VERSION ""

NS_ :

BS_:

BU_: ZOMBIE LEAFSIM

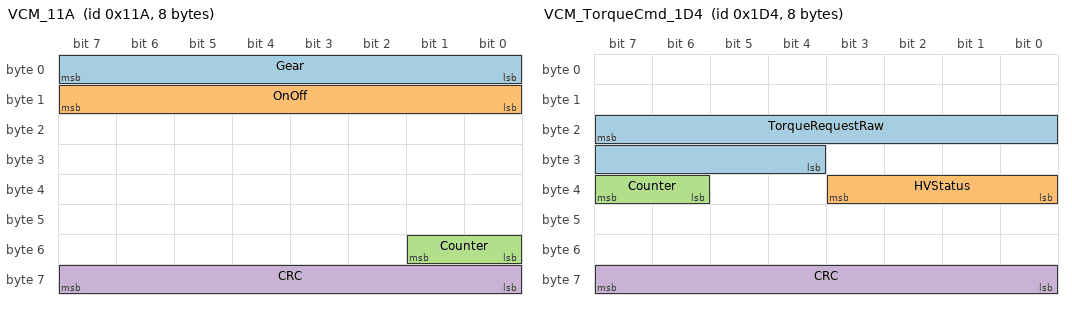
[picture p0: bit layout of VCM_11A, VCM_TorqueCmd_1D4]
BO_ 282 VCM_11A: 8 ZOMBIE
 SG_ Gear : 0|8@1+ (1,0) [0|255] "" LEAFSIM
 SG_ OnOff : 8|8@1+ (1,0) [0|255] "" LEAFSIM
 SG_ Counter : 48|2@1+ (1,0) [0|3] "" LEAFSIM
 SG_ CRC : 56|8@1+ (1,0) [0|255] "" LEAFSIM

BO_ 468 VCM_TorqueCmd_1D4: 8 ZOMBIE
 SG_ TorqueRequestRaw : 23|12@0- (1,0) [-2048|2047] "" LEAFSIM
 SG_ HVStatus : 32|4@1+ (1,0) [0|15] "" LEAFSIM
 SG_ Counter : 38|2@1+ (1,0) [0|3] "" LEAFSIM
 SG_ CRC : 56|8@1+ (1,0) [0|255] "" LEAFSIM

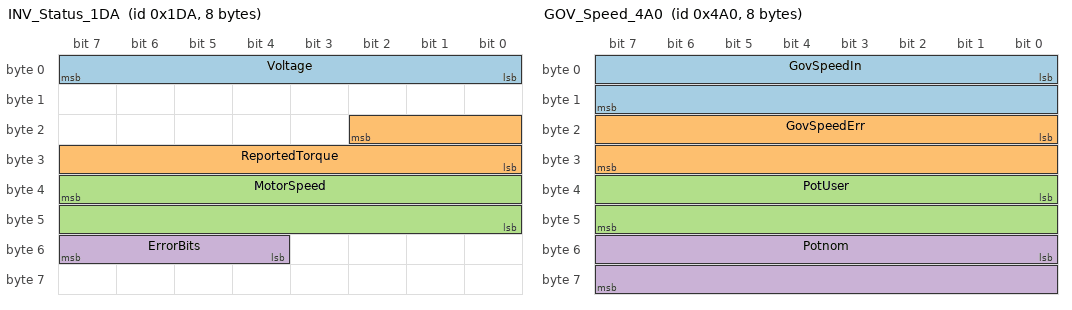
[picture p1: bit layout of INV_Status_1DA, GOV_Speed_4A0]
BO_ 474 INV_Status_1DA: 8 LEAFSIM
 SG_ Voltage : 0|8@1+ (2,0) [0|510] "V" ZOMBIE
 SG_ ReportedTorque : 18|11@0- (0.5,0) [-512|511.5] "Nm" ZOMBIE
 SG_ MotorSpeed : 39|16@0- (0.5,0) [-16384|16383.5] "rpm" ZOMBIE
 SG_ ErrorBits : 52|4@1+ (1,0) [0|15] "" ZOMBIE

BO_ 1184 GOV_Speed_4A0: 8 ZOMBIE
 SG_ GovSpeedIn : 0|16@1+ (1,0) [0|65535] "rpm" LEAFSIM
 SG_ GovSpeedErr : 16|16@1- (0.125,0) [-4096|4095.875] "rpm" LEAFSIM
 SG_ PotUser : 32|16@1- (0.01,0) [-327.68|327.67] "%" LEAFSIM
 SG_ Potnom : 48|16@1- (0.01,0) [-327.68|327.67] "%" LEAFSIM

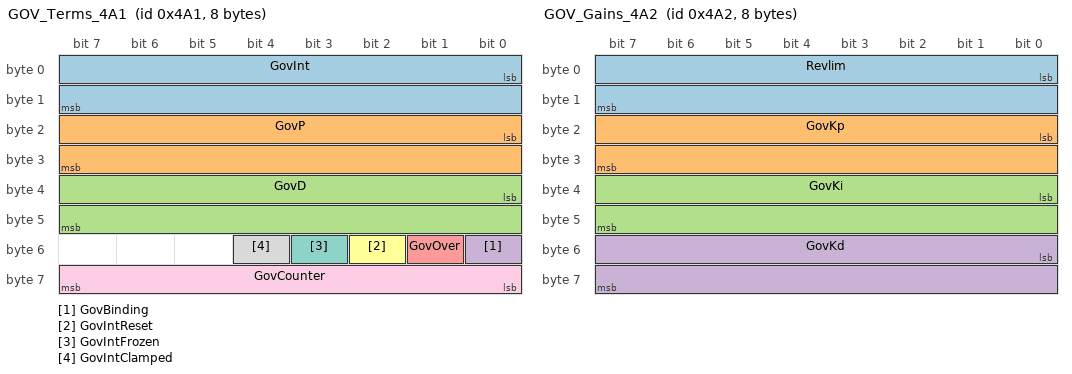
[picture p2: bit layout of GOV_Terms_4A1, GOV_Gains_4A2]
BO_ 1185 GOV_Terms_4A1: 8 ZOMBIE
 SG_ GovInt : 0|16@1- (0.01,0) [-327.68|327.67] "%" LEAFSIM
 SG_ GovP : 16|16@1- (0.01,0) [-327.68|327.67] "%" LEAFSIM
 SG_ GovD : 32|16@1- (0.01,0) [-327.68|327.67] "%" LEAFSIM
 SG_ GovBinding : 48|1@1+ (1,0) [0|1] "" LEAFSIM
 SG_ GovOver : 49|1@1+ (1,0) [0|1] "" LEAFSIM
 SG_ GovIntReset : 50|1@1+ (1,0) [0|1] "" LEAFSIM
 SG_ GovIntFrozen : 51|1@1+ (1,0) [0|1] "" LEAFSIM
 SG_ GovIntClamped : 52|1@1+ (1,0) [0|1] "" LEAFSIM
 SG_ GovCounter : 56|8@1+ (1,0) [0|255] "" LEAFSIM

BO_ 1186 GOV_Gains_4A2: 8 ZOMBIE
 SG_ Revlim : 0|16@1+ (1,0) [0|65535] "rpm" LEAFSIM
 SG_ GovKp : 16|16@1+ (0.03125,0) [0|2047.97] "0.01%/rpm" LEAFSIM
 SG_ GovKi : 32|16@1+ (0.03125,0) [0|2047.97] "0.001%/rpm/tk" LEAFSIM
 SG_ GovKd : 48|16@1+ (0.03125,0) [0|2047.97] "%/(rpm/tick)" LEAFSIM

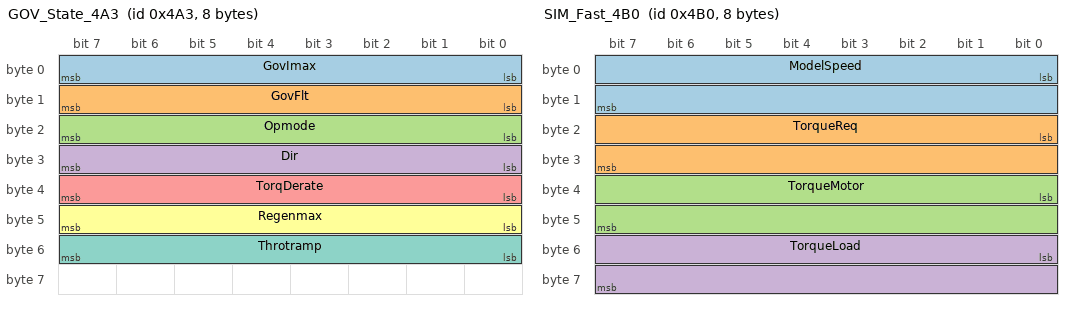
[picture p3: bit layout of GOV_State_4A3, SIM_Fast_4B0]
BO_ 1187 GOV_State_4A3: 8 ZOMBIE
 SG_ GovImax : 0|8@1+ (1,0) [0|255] "%" LEAFSIM
 SG_ GovFlt : 8|8@1+ (1,0) [0|6] "" LEAFSIM
 SG_ Opmode : 16|8@1+ (1,0) [0|255] "" LEAFSIM
 SG_ Dir : 24|8@1- (1,0) [-1|1] "" LEAFSIM
 SG_ TorqDerate : 32|8@1+ (1,0) [0|255] "" LEAFSIM
 SG_ Regenmax : 40|8@1- (1,0) [-128|127] "%" LEAFSIM
 SG_ Throtramp : 48|8@1+ (1,0) [0|255] "%/10ms" LEAFSIM

BO_ 1200 SIM_Fast_4B0: 8 LEAFSIM
 SG_ ModelSpeed : 0|16@1- (0.5,0) [-16384|16383.5] "rpm" ZOMBIE
 SG_ TorqueReq : 16|16@1- (0.1,0) [-3276.8|3276.7] "Nm" ZOMBIE
 SG_ TorqueMotor : 32|16@1- (0.1,0) [-3276.8|3276.7] "Nm" ZOMBIE
 SG_ TorqueLoad : 48|16@1- (0.1,0) [-3276.8|3276.7] "Nm" ZOMBIE

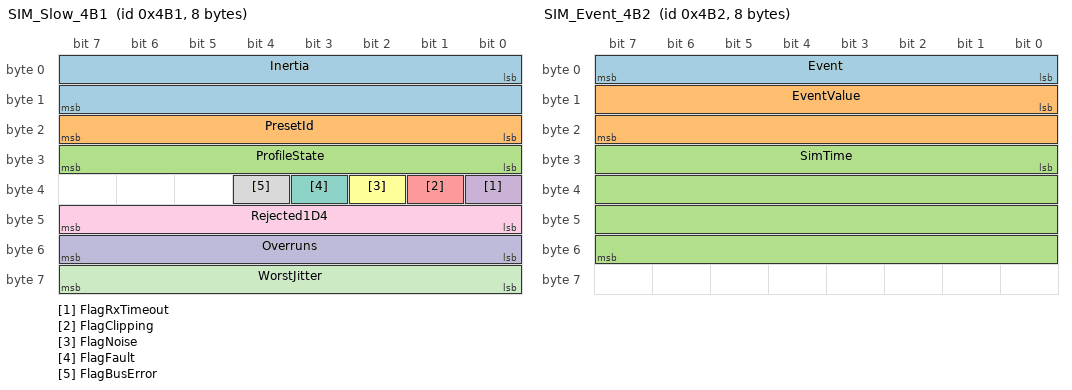
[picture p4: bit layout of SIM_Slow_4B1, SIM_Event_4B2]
BO_ 1201 SIM_Slow_4B1: 8 LEAFSIM
 SG_ Inertia : 0|16@1+ (0.001,0) [0|65.535] "kg.m2" ZOMBIE
 SG_ PresetId : 16|8@1+ (1,0) [0|255] "" ZOMBIE
 SG_ ProfileState : 24|8@1+ (1,0) [0|3] "" ZOMBIE
 SG_ FlagRxTimeout : 32|1@1+ (1,0) [0|1] "" ZOMBIE
 SG_ FlagClipping : 33|1@1+ (1,0) [0|1] "" ZOMBIE
 SG_ FlagNoise : 34|1@1+ (1,0) [0|1] "" ZOMBIE
 SG_ FlagFault : 35|1@1+ (1,0) [0|1] "" ZOMBIE
 SG_ FlagBusError : 36|1@1+ (1,0) [0|1] "" ZOMBIE
 SG_ Rejected1D4 : 40|8@1+ (1,0) [0|255] "" ZOMBIE
 SG_ Overruns : 48|8@1+ (1,0) [0|255] "" ZOMBIE
 SG_ WorstJitter : 56|8@1+ (0.1,0) [0|25.5] "ms" ZOMBIE

BO_ 1202 SIM_Event_4B2: 8 LEAFSIM
 SG_ Event : 0|8@1+ (1,0) [0|255] "" ZOMBIE
 SG_ EventValue : 8|16@1+ (1,0) [0|65535] "" ZOMBIE
 SG_ SimTime : 24|32@1+ (1,0) [0|4294967295] "ms" ZOMBIE

BO_ 1370 INV_Temps_55A: 8 LEAFSIM
 SG_ MotorTemp : 8|8@1+ (0.555556,-17.7778) [-17.7778|123.889] "degC" ZOMBIE
 SG_ InverterTemp : 16|8@1+ (0.555556,-17.7778) [-17.7778|123.889] "degC" ZOMBIE

CM_ BU_ ZOMBIE "ZombieVerter VCU, real hardware under test.";
CM_ BU_ LEAFSIM "LilyGo T-CAN485 simulating the Nissan Leaf inverter, motor and load.";
CM_ BO_ 282 "Leaf VCM gear and on/off, sent by the Zombie every 10 ms in run mode only.";
CM_ SG_ 282 Gear "0x4E drive, 0x2E reverse, 0x01 park.";
CM_ SG_ 282 OnOff "0x40 car on, 0x80 off (charging).";
CM_ BO_ 468 "Leaf VCM torque request, sent by the Zombie every 10 ms in run mode only.";
CM_ SG_ 468 TorqueRequestRaw "Counts. Zombie: raw = torquePercent * 2047 / 100 (LeafINV::SetTorque). Nm = raw * kT; kT 0.25 Nm, confirmed from tractor logs (plan section 12, V1). Decoded Nm is in 0x4B0 from M5.";
CM_ SG_ 468 HVStatus "7 HV on, 3 precharge, 2 off.";
CM_ SG_ 468 CRC "Nissan CRC-8, polynomial 0x85, over bytes 0-6.";
CM_ BO_ 474 "Leaf inverter status, sent by the simulator every 10 ms from power-up.";
CM_ SG_ 474 Voltage "Zombie uses it as udc only below 420 V with ShuntType = 0.";
CM_ SG_ 474 ReportedTorque "Layout confirmed from tractor logs (plan section 12, V3). The simulator sends its motor torque after the envelope and lag (SIM_REPORT_TORQUE). Not read by the Zombie.";
CM_ SG_ 474 MotorSpeed "True signed speed. The Zombie decodes reverse speeds 1 rpm high.";
CM_ SG_ 474 ErrorBits "Byte 6 bits 4-7. Zombie: error when (byte6 & 0xB0) != 0. Simulator fault sets bit 4.";
CM_ BO_ 1370 "Leaf inverter temperatures, sent by the simulator every 100 ms. Degrees Fahrenheit on the bus.";
CM_ BO_ 1184 "Zombie governor log, every 10 ms in run mode with GovLog = On (branch gov-logging).";
CM_ SG_ 1184 GovSpeedIn "Absolute speed passed to SpeedLimitCommand (previous tick's speed).";
CM_ SG_ 1184 GovSpeedErr "revlim minus the governor's filtered speed.";
CM_ SG_ 1184 PotUser "Driver throttle demand before any limit.";
CM_ SG_ 1184 Potnom "Final throttle after all limits and the ramp, before direction.";
CM_ BO_ 1185 "Zombie governor terms, every 10 ms in run mode with GovLog = On. Governor output = GovP + GovD + GovInt.";
CM_ SG_ 1185 GovBinding "The governor reduced the throttle this tick.";
CM_ SG_ 1185 GovIntFrozen "Integral held: the pedal, not the governor, was the binding limit.";
CM_ SG_ 1185 GovCounter "Increments every frame; gaps mean dropped frames.";
CM_ BO_ 1186 "Zombie governor gains as entered, every 100 ms with GovLog = On.";
CM_ BO_ 1187 "Zombie governor settings and state, every 100 ms with GovLog = On.";
CM_ SG_ 1187 GovFlt "Speed filter shift: 4 is about 155 ms, 3 about 75 ms, 2 about 35 ms.";
CM_ BO_ 1200 "Simulator model state, every 10 ms. ModelSpeed has no measurement noise.";
CM_ SG_ 1200 TorqueReq "0x1D4 request as decoded with kT; zero after the 100 ms timeout.";
CM_ SG_ 1200 TorqueMotor "Motor torque after the envelope and lag.";
CM_ SG_ 1200 TorqueLoad "Signed load torque on the shaft: friction plus loads.";
CM_ BO_ 1201 "Simulator status, every 100 ms.";
CM_ SG_ 1201 Inertia "Inertia in use, including step dJ or the profile's inertia column.";
CM_ SG_ 1201 PresetId "0 none, 1 noload, 2 topper, 3 baler, 4 pto_step, 5 default, 200 SD-only preset.";
CM_ SG_ 1201 Rejected1D4 "0x1D4 frames rejected for CRC or length, wrapping.";
CM_ SG_ 1201 Overruns "10 ms tick overruns, wrapping.";
CM_ SG_ 1201 WorstJitter "Worst tick period error in the last second.";
CM_ BO_ 1202 "Simulator event, sent when a console command changes the simulation.";
CM_ SG_ 1202 EventValue "Marker number, load torque in Nm (signed 16-bit), preset id, parameter index, or profile row.";

VAL_ 282 Gear 78 "Drive" 46 "Reverse" 1 "Park" ;
VAL_ 468 HVStatus 7 "HV on" 3 "Precharge" 2 "Off" ;
VAL_ 1187 Opmode 0 "Off" 1 "Run" 2 "Precharge" 3 "PchFail" 4 "Charge" 5 "Preheat" ;
VAL_ 1201 ProfileState 0 "Idle" 1 "Loaded" 2 "Running" 3 "Finished" ;
VAL_ 1202 Event 1 "Marker" 2 "Load" 3 "ProfileStart" 4 "ProfileStop" 5 "Preset" 6 "ParamChange" 7 "ZParam" ;
